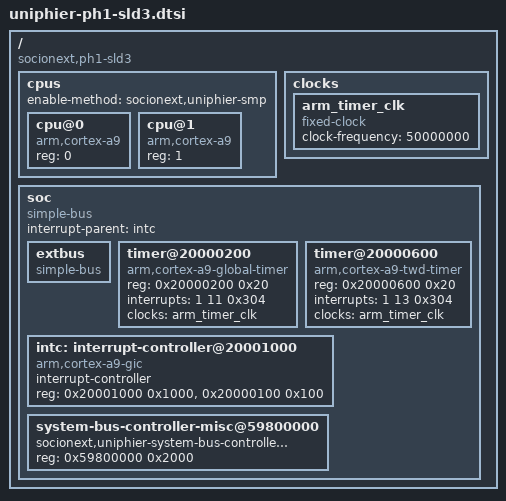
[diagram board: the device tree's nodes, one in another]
/*
 * Device Tree Source for UniPhier PH1-sLD3 SoC
 *
 * Copyright (C) 2015 Masahiro Yamada <yamada.masahiro@socionext.com>
 *
 * This file is dual-licensed: you can use it either under the terms
 * of the GPL or the X11 license, at your option. Note that this dual
 * licensing only applies to this file, and not this project as a
 * whole.
 *
 *  a) This file is free software; you can redistribute it and/or
 *     modify it under the terms of the GNU General Public License as
 *     published by the Free Software Foundation; either version 2 of the
 *     License, or (at your option) any later version.
 *
 *     This file is distributed in the hope that it will be useful,
 *     but WITHOUT ANY WARRANTY; without even the implied warranty of
 *     MERCHANTABILITY or FITNESS FOR A PARTICULAR PURPOSE.  See the
 *     GNU General Public License for more details.
 *
 * Or, alternatively,
 *
 *  b) Permission is hereby granted, free of charge, to any person
 *     obtaining a copy of this software and associated documentation
 *     files (the "Software"), to deal in the Software without
 *     restriction, including without limitation the rights to use,
 *     copy, modify, merge, publish, distribute, sublicense, and/or
 *     sell copies of the Software, and to permit persons to whom the
 *     Software is furnished to do so, subject to the following
 *     conditions:
 *
 *     The above copyright notice and this permission notice shall be
 *     included in all copies or substantial portions of the Software.
 *
 *     THE SOFTWARE IS PROVIDED "AS IS", WITHOUT WARRANTY OF ANY KIND,
 *     EXPRESS OR IMPLIED, INCLUDING BUT NOT LIMITED TO THE WARRANTIES
 *     OF MERCHANTABILITY, FITNESS FOR A PARTICULAR PURPOSE AND
 *     NONINFRINGEMENT. IN NO EVENT SHALL THE AUTHORS OR COPYRIGHT
 *     HOLDERS BE LIABLE FOR ANY CLAIM, DAMAGES OR OTHER LIABILITY,
 *     WHETHER IN AN ACTION OF CONTRACT, TORT OR OTHERWISE, ARISING
 *     FROM, OUT OF OR IN CONNECTION WITH THE SOFTWARE OR THE USE OR
 *     OTHER DEALINGS IN THE SOFTWARE.
 */

/include/ "skeleton.dtsi"

/ {
	compatible = "socionext,ph1-sld3";

	cpus {
		#address-cells = <1>;
		#size-cells = <0>;
		enable-method = "socionext,uniphier-smp";

		cpu@0 {
			device_type = "cpu";
			compatible = "arm,cortex-a9";
			reg = <0>;
		};

		cpu@1 {
			device_type = "cpu";
			compatible = "arm,cortex-a9";
			reg = <1>;
		};
	};

	clocks {
		arm_timer_clk: arm_timer_clk {
			#clock-cells = <0>;
			compatible = "fixed-clock";
			clock-frequency = <50000000>;
		};
	};

	soc {
		compatible = "simple-bus";
		#address-cells = <1>;
		#size-cells = <1>;
		ranges;
		interrupt-parent = <&intc>;

		extbus: extbus {
			compatible = "simple-bus";
			#address-cells = <2>;
			#size-cells = <1>;
		};

		timer@20000200 {
			compatible = "arm,cortex-a9-global-timer";
			reg = <0x20000200 0x20>;
			interrupts = <1 11 0x304>;
			clocks = <&arm_timer_clk>;
		};

		timer@20000600 {
			compatible = "arm,cortex-a9-twd-timer";
			reg = <0x20000600 0x20>;
			interrupts = <1 13 0x304>;
			clocks = <&arm_timer_clk>;
		};

		intc: interrupt-controller@20001000 {
			compatible = "arm,cortex-a9-gic";
			#interrupt-cells = <3>;
			interrupt-controller;
			reg = <0x20001000 0x1000>,
			      <0x20000100 0x100>;
		};

		system-bus-controller-misc@59800000 {
			compatible = "socionext,uniphier-system-bus-controller-misc",
				     "syscon";
			reg = <0x59800000 0x2000>;
		};
	};
};
